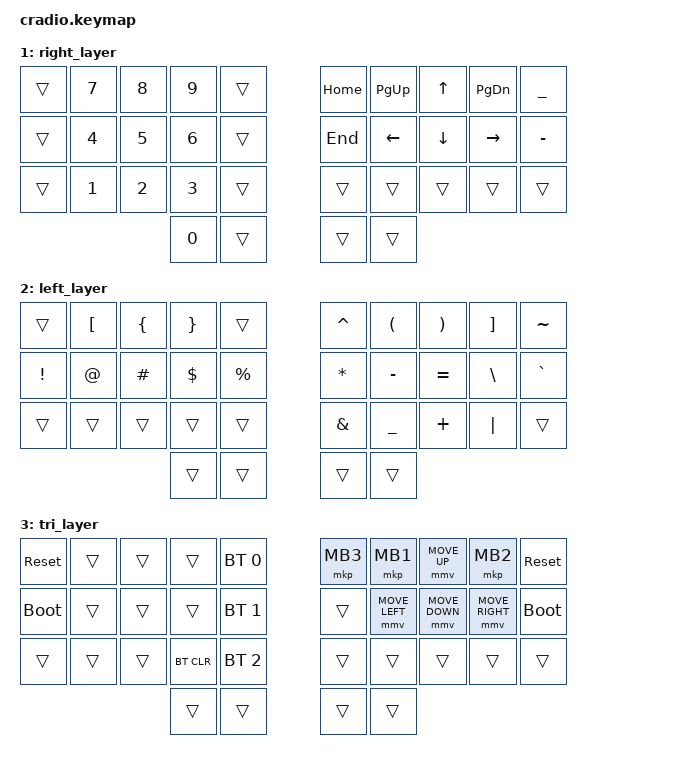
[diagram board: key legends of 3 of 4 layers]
// Copyright (c) 2022 The ZMK Contributors
// SPDX-License-Identifier: MIT

#include <behaviors.dtsi>
#include <dt-bindings/zmk/keys.h>
#include <dt-bindings/zmk/bt.h>
#include <dt-bindings/zmk/pointing.h>


// Key helpers
#define KEYS_L 0 1 2 3 4 10 11 12 13 14 20 21 22 23 24
#define KEYS_R 5 6 7 8 9 15 16 17 18 19 25 26 27 28 29
#define THUMBS 30 31 32 33

// Home row mods macro
#define HRML(k1,k2,k3,k4) &hml LGUI  k1  &hml LALT  k2  &hml LCTRL k3  &kp  k4
#define HRMR(k1,k2,k3,k4) &kp  k1        &hmr RCTRL k2  &hmr RALT  k3  &hmr RGUI  k4
#define SFT_BSPC &mt LSHFT BSPC

/ {
    behaviors {
        hml: home_row_left {
            compatible = "zmk,behavior-hold-tap";
            flavor = "balanced";
            #binding-cells = <2>;
            tapping-term-ms = <280>;
            quick-tap-ms = <175>;
            require-prior-idle-ms = <150>;
            bindings = <&kp>, <&kp>;
            hold-trigger-key-positions = <KEYS_R THUMBS>;
            hold-trigger-on-release;
        };
        hmr: home_row_right {
            compatible = "zmk,behavior-hold-tap";
            flavor = "balanced";
            #binding-cells = <2>;
            tapping-term-ms = <280>;
            quick-tap-ms = <175>;
            require-prior-idle-ms = <150>;
            bindings = <&kp>, <&kp>;
            hold-trigger-key-positions = <KEYS_L THUMBS>;
            hold-trigger-on-release;
        };
    };

    conditional_layers {
        compatible = "zmk,conditional-layers";
        tri_layer {
            if-layers = <1 2>;
            then-layer = <3>;
        };
    };

    combo {
      compatible = "zmk,combos";
      combo_tab {
        timeout-ms = <18>;
        require-prior-idle-ms = <150>;
        key-positions = <0 1>;
        bindings = <&kp TAB>;
      };
      combo_esc {
        timeout-ms = <18>;
        require-prior-idle-ms = <150>;
        key-positions = <10 11>;
        bindings = <&kp ESC>;
      };
      combo_min {
        timeout-ms = <18>;
        require-prior-idle-ms = <150>;
        key-positions = <8 9>;
        bindings = <&kp MINUS>;
      };
      combo_sqt {
        timeout-ms = <18>;
        require-prior-idle-ms = <150>;
        key-positions = <18 19>;
        bindings = <&kp SQT>;
      };
    };
    
    keymap {
        compatible = "zmk,keymap";
        default_layer {
            bindings = <
        //╭──────────┬──────────┬──────────┬──────────┬──────────╮   ╭──────────┬──────────┬──────────┬──────────┬──────────╮
        //│  Q       │  W       │  F       │  P       │  G       │   │  J       │  L       │  U       │  Y       │  ; :     │
            &kp Q      &kp W      &kp F      &kp P      &kp G          &kp J      &kp L      &kp U      &kp Y      &kp SEMI
        //├──────────┼──────────┼──────────┼──────────┼──────────┤   ├──────────┼──────────┼──────────┼──────────┼──────────┤
        //│  A       │  R       │  S       │  T       │  D       │   │  H       │  N       │  E       │  I       │  O       │
            HRML(A,        R,         S,         T)     &kp D          &kp H      HRMR(N,        E,         I,        O)
        //├──────────┼──────────┼──────────┼──────────┼──────────┤   ├──────────┼──────────┼──────────┼──────────┼──────────┤
        //│  Z       │  X       │  C       │  V       │  B       │   │  K       │  M       │ , <      │ . >      │ / ?      │
            &kp Z      &kp X      &kp C      &kp V      &kp B          &kp K      &kp M      &kp COMMA  &kp DOT    &kp FSLH
        //╰──────────┴──────────┴──────────┼──────────┼──────────┤   ├──────────┼──────────┼──────────┴──────────┴──────────╯
                                            &lt 1 DEL  SFT_BSPC       &lt 1 SPACE &lt 2 ENTER
        //                                 ╰──────────┴──────────╯   ╰──────────┴──────────╯
            >;
        };

        right_layer {
            bindings = <
        //╭──────────┬──────────┬──────────┬──────────┬──────────╮   ╭──────────┬──────────┬──────────┬──────────┬──────────╮
        //│          │  7       │  8       │  9       │          │   │ HOME     │ PAGE UP  │ UP       │ PAGE DOWN│  _       │
            &trans     &kp N7     &kp N8     &kp N9     &trans         &kp HOME   &kp PG_UP  &kp UP    &kp PG_DN  &kp UNDER
        //├──────────┼──────────┼──────────┼──────────┼──────────┤   ├──────────┼──────────┼──────────┼──────────┼──────────┤
        //│          │  4       │  5       │  6       │          │   │ END     │ DOWN     │ UP       │ RIGHT    │  -       │
            &trans     &kp N4     &kp N5     &kp N6     &trans         &kp END   &kp LEFT  &kp DOWN  &kp RIGHT   &kp MINUS
        //├──────────┼──────────┼──────────┼──────────┼──────────┤   ├──────────┼──────────┼──────────┼──────────┼──────────┤
        //│          │  1       │  2       │  3       │          │   │          │          │          │          │          │
            &trans     &kp N1     &kp N2     &kp N3     &trans         &trans     &trans     &trans     &trans     &trans
        //╰──────────┴──────────┴──────────┼──────────┼──────────┤   ├──────────┼──────────┼──────────┴──────────┴──────────╯
                                             &kp N0     &trans         &trans     &trans
        //                                 ╰──────────┴──────────╯   ╰──────────┴──────────╯
            >;
        };

        left_layer {
            bindings = <
        //╭──────────┬──────────┬──────────┬──────────┬──────────╮   ╭──────────┬──────────┬──────────┬──────────┬──────────╮
        //│          │  [       │  {       │  }       │          │   │  ^       │  (       │  )       │  ]       │  ~       │
            &trans     &kp LBKT   &kp LBRC   &kp RBRC   &trans         &kp CARET  &kp LPAR   &kp RPAR   &kp RBKT   &kp TILDE
        //├──────────┼──────────┼──────────┼──────────┼──────────┤   ├──────────┼──────────┼──────────┼──────────┼──────────┤
        //│  !       │  @       │  #       │  $       │  %       │   │  *       │  -       │  =       │  \       │  `       │
            &kp EXCL   &kp AT     &kp HASH   &kp DLLR   &kp PRCNT      &kp ASTRK  &kp MINUS  &kp EQUAL  &kp BSLH   &kp GRAVE
        //├──────────┼──────────┼──────────┼──────────┼──────────┤   ├──────────┼──────────┼──────────┼──────────┼──────────┤
        //│          │          │          │          │          │   │  &       │  _       │  +       │  │       │          │
            &trans     &trans     &trans     &trans     &trans         &kp AMPS   &kp UNDER  &kp PLUS   &kp PIPE   &trans
        //╰──────────┴──────────┴──────────┼──────────┼──────────┤   ├──────────┼──────────┼──────────┴──────────┴──────────╯
                                             &trans     &trans         &trans     &trans
        //                                 ╰──────────┴──────────╯   ╰──────────┴──────────╯
            >;
        };

        /* Backup original left layer
        left_layer {
            bindings = <
        //╭──────────┬──────────┬──────────┬──────────┬──────────╮   ╭──────────┬──────────┬──────────┬──────────┬──────────╮
        //│          │  [       │  {       │  }       │          │   │  ^       │  (       │  )       │  ]       │  ~       │
            &trans     &kp LBKT   &kp LBRC   &kp RBRC   &trans         &kp CARET  &kp LPAR   &kp RPAR   &kp RBKT   &kp TILDE
        //├──────────┼──────────┼──────────┼──────────┼──────────┤   ├──────────┼──────────┼──────────┼──────────┼──────────┤
        //│  !       │  @       │  #       │  $       │  %       │   │  *       │  -       │  =       │  \       │  `       │
            &kp EXCL   &kp AT     &kp HASH   &kp DLLR   &kp PRCNT      &kp ASTRK  &kp MINUS  &kp EQUAL  &kp BSLH   &kp GRAVE
        //├──────────┼──────────┼──────────┼──────────┼──────────┤   ├──────────┼──────────┼──────────┼──────────┼──────────┤
        //│          │          │          │          │          │   │  &       │  _       │  +       │  │       │          │
            &trans     &trans     &trans     &trans     &trans         &kp AMPS   &kp UNDER  &kp PLUS   &kp PIPE   &trans
        //╰──────────┴──────────┴──────────┼──────────┼──────────┤   ├──────────┼──────────┼──────────┴──────────┴──────────╯
                                             &trans     &trans         &trans     &trans
        //                                 ╰──────────┴──────────╯   ╰──────────┴──────────╯
            >;
        };
        */

        tri_layer {
            bindings = <
        //╭──────────┬──────────┬──────────┬──────────┬──────────╮   ╭──────────┬───────────────┬──────────┬──────────┬──────────╮
        //│ RESET    │          │          │          │PROFILE 0 │   │          │               │          │          │  RESET   │
           &sys_reset  &trans     &trans     &trans    &bt BT_SEL 0    &mkp MB3  &mkp MB1       &mmv MOVE_UP &mkp MB2  &sys_reset
        //├──────────┼──────────┼──────────┼──────────┼──────────┤   ├──────────┼─────────     ─┼──────────┼──────────┼──────────┤
        //│BOOTLOADER│          │          │          │PROFILE 1 │   │          │               │          │          │BOOTLOADER│
          &bootloader  &trans     &trans     &trans    &bt BT_SEL 1    &trans   &mmv MOVE_LEFT  &mmv MOVE_DOWN &mmv MOVE_RIGHT    &bootloader
        //├──────────┼──────────┼──────────┼──────────┼──────────┤   ├──────────┼──────────┼──────────┼──────────┼──────────┤
        //│          │          │          │ CLEAR BT │PROFILE 2 │   │          │          │          │          │          │
            &trans     &trans     &trans    &bt BT_CLR &bt BT_SEL 2    &trans     &trans     &trans     &trans     &trans
        //╰──────────┴──────────┴──────────┼──────────┼──────────┤   ├──────────┼──────────┼──────────┴──────────┴──────────╯
                                             &trans     &trans         &trans     &trans
        //                                 ╰──────────┴──────────╯   ╰──────────┴──────────╯
            >;
        };
    };
};
